# STM32N645 register map
File version: 1.0
CPU: CM55 r0p1, little endian, no MPU, FPU, vendor SysTick, 8 interrupt priority bits
Registers are 32-bit, read-write, reset 0x0 unless marked. A register's access mark holds for its fields unless they carry their own. Offsets are from the block's base; [hi:lo] are bit positions; {n}, {i} and the like mark numbered series.

## TIM15 — General purpose timers
Base 0x42004000
Same registers: TIM15_S 0x52004000
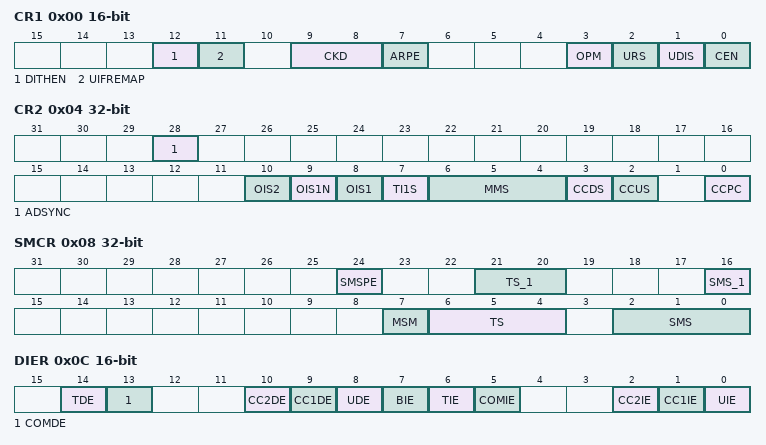
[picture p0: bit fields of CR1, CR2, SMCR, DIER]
0x00 CR1 16-bit — TIM15 control register 1
  [12] DITHEN — Dithering enable
  [11] UIFREMAP — UIF status bit remapping
  [9:8] CKD — Clock division
  [7] ARPE — Auto-reload preload enable
  [3] OPM — One-pulse mode
  [2] URS — Update request source
  [1] UDIS — Update disable
  [0] CEN — Counter enable
0x04 CR2 — TIM15 control register 2
  [28] ADSYNC — ADC synchronization
  [10] OIS2 — Output idle state 2 (tim_oc2 output)
  [9] OIS1N — Output Idle state 1 (tim_oc1n output)
  [8] OIS1 — Output Idle state 1 (tim_oc1 output)
  [7] TI1S — tim_ti1 selection
  [6:4] MMS — Master mode selection
  [3] CCDS — Capture/compare DMA selection
  [2] CCUS — Capture/compare control update selection
  [0] CCPC — Capture/compare preloaded control
0x08 SMCR — TIM15 slave mode control register
  [24] SMSPE — SMS preload enable
  [21:20] TS_1 — TS[4:3]
  [16] SMS_1 — SMS[3]
  [7] MSM — Master/slave mode
  [6:4] TS — TS[0]: Trigger selection
  [2:0] SMS — SMS[0]: Slave mode selection
0x0C DIER 16-bit — TIM15 DMA/interrupt enable register
  [14] TDE — Trigger DMA request enable
  [13] COMDE — COM DMA request enable
  [10] CC2DE — Capture/Compare 2 DMA request enable
  [9] CC1DE — Capture/Compare 1 DMA request enable
  [8] UDE — Update DMA request enable
  [7] BIE — Break interrupt enable
  [6] TIE — Trigger interrupt enable
  [5] COMIE — COM interrupt enable
  [2] CC2IE — Capture/Compare 2 interrupt enable
  [1] CC1IE — Capture/Compare 1 interrupt enable
  [0] UIE — Update interrupt enable
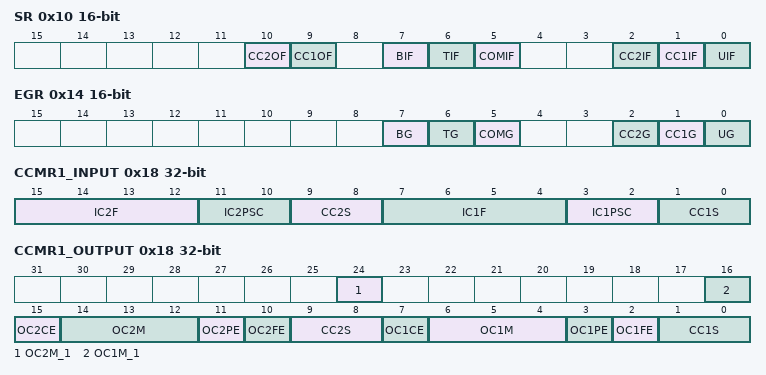
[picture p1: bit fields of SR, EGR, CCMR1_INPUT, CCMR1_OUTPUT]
0x10 SR 16-bit — TIM15 status register
  [10] CC2OF — Capture/Compare 2 overcapture flag
  [9] CC1OF — Capture/Compare 1 overcapture flag
  [7] BIF — Break interrupt flag
  [6] TIF — Trigger interrupt flag
  [5] COMIF — COM interrupt flag
  [2] CC2IF — Capture/Compare 2 interrupt flag
  [1] CC1IF — Capture/Compare 1 interrupt flag
  [0] UIF — Update interrupt flag
0x14 EGR 16-bit access per field — TIM15 event generation register
  [7] BG wo — Break generation
  [6] TG wo — Trigger generation
  [5] COMG rw — Capture/Compare control update generation
  [2] CC2G wo — Capture/Compare 2 generation
  [1] CC1G wo — Capture/Compare 1 generation
  [0] UG wo — Update generation
0x18 CCMR1_INPUT — TIM15 capture/compare mode register 1
  [15:12] IC2F — Input capture 2 filter
  [11:10] IC2PSC — Input capture 2 prescaler
  [9:8] CC2S — Capture/Compare 2 selection
  [7:4] IC1F — Input capture 1 filter
  [3:2] IC1PSC — Input capture 1 prescaler
  [1:0] CC1S — Capture/Compare 1 selection
0x18 CCMR1_OUTPUT (alternate view of CCMR1_INPUT) — TIM15 capture/compare mode register 1
  [24] OC2M_1 — OC2M[3]
  [16] OC1M_1 — OC1M[3]
  [15] OC2CE — Output compare 2 clear enable
  [14:12] OC2M — OC2M[2:0]: Output compare 2 mode
  [11] OC2PE — Output compare 2 preload enable
  [10] OC2FE — Output compare 2 fast enable
  [9:8] CC2S — Capture/Compare 2 selection
  [7] OC1CE — Output compare 1 clear enable
  [6:4] OC1M — OC1M[2:0]: Output compare 1 mode
  [3] OC1PE — Output Compare 1 preload enable
  [2] OC1FE — Output Compare 1 fast enable
  [1:0] CC1S — Capture/Compare 1 selection
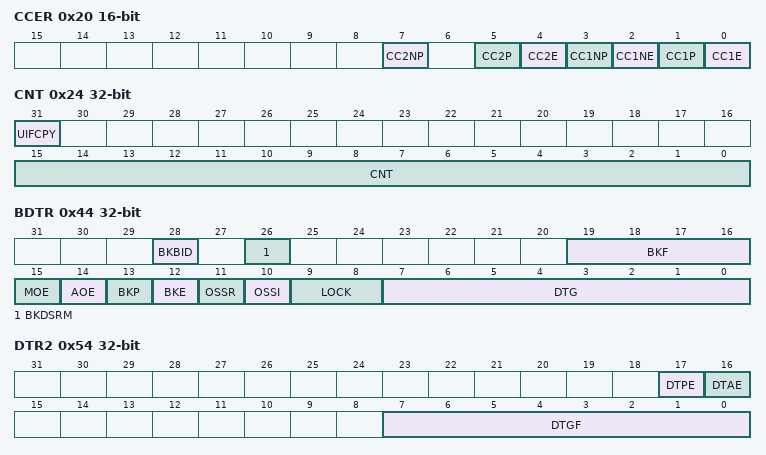
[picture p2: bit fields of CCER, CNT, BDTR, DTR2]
0x20 CCER 16-bit — TIM15 capture/compare enable register
  [7] CC2NP — Capture/Compare 2 complementary output polarity
  [5] CC2P — Capture/Compare 2 output polarity
  [4] CC2E — Capture/Compare 2 output enable
  [3] CC1NP — Capture/Compare 1 complementary output polarity
  [2] CC1NE — Capture/Compare 1 complementary output enable
  [1] CC1P — Capture/Compare 1 output polarity
  [0] CC1E — Capture/Compare 1 output enable
0x24 CNT access per field — TIM15 counter
  [31] UIFCPY ro — UIF Copy
  [15:0] CNT rw — Counter value
0x28 PSC 16-bit — TIM15 prescaler
  [15:0] PSC — Prescaler value
0x2C ARR reset 0xFFFF — TIM15 auto-reload register
  [19:0] ARR — Auto-reload value
0x30 RCR 16-bit — TIM15 repetition counter register
  [7:0] REP — Repetition counter reload value
0x34 CCR1 — TIM15 capture/compare register 1
  [19:0] CCR1 — Capture/compare 1 value
0x38 CCR2 — TIM15 capture/compare register 2
  [19:0] CCR2 — Capture/compare 2 value
0x44 BDTR — TIM15 break and dead-time register
  [28] BKBID — Break bidirectional
  [26] BKDSRM — Break disarm
  [19:16] BKF — Break filter
  [15] MOE — Main output enable
  [14] AOE — Automatic output enable
  [13] BKP — Break polarity
  [12] BKE — Break enable
  [11] OSSR — Off-state selection for Run mode
  [10] OSSI — Off-state selection for Idle mode
  [9:8] LOCK — Lock configuration
  [7:0] DTG — Dead-time generator setup
0x54 DTR2 — TIM15 timer deadtime register 2
  [17] DTPE — Deadtime preload enable
  [16] DTAE — Deadtime asymmetric enable
  [7:0] DTGF — Dead-time falling edge generator setup
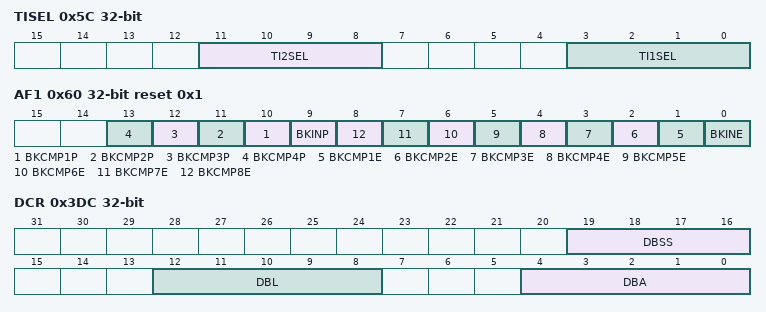
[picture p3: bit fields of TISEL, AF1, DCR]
0x5C TISEL — TIM15 input selection register
  [11:8] TI2SEL — selects tim_ti2_in[15:0] input
  [3:0] TI1SEL — selects tim_ti1_in[15:0] input
0x60 AF1 reset 0x1 — TIM15 alternate function register 1
  [n+9] BKCMP{n}P (n=1..4) — tim_brk_cmp{n} input polarity
  [9] BKINP — TIMx_BKIN input polarity
  [n] BKCMP{n}E (n=1..8) — tim_brk_cmp{n} enable
  [0] BKINE — TIMx_BKIN input enable
0x64 AF2 — TIM15 alternate function register 2
  [18:16] OCRSEL — ocref_clr source selection
0x3DC DCR — TIM15 DMA control register
  [19:16] DBSS — DMA burst source selection
  [12:8] DBL — DMA burst length
  [4:0] DBA — DMA base address
0x3E0 DMAR — TIM15 DMA address for full transfer
  [31:0] DMAB — DMA register for burst accesses
